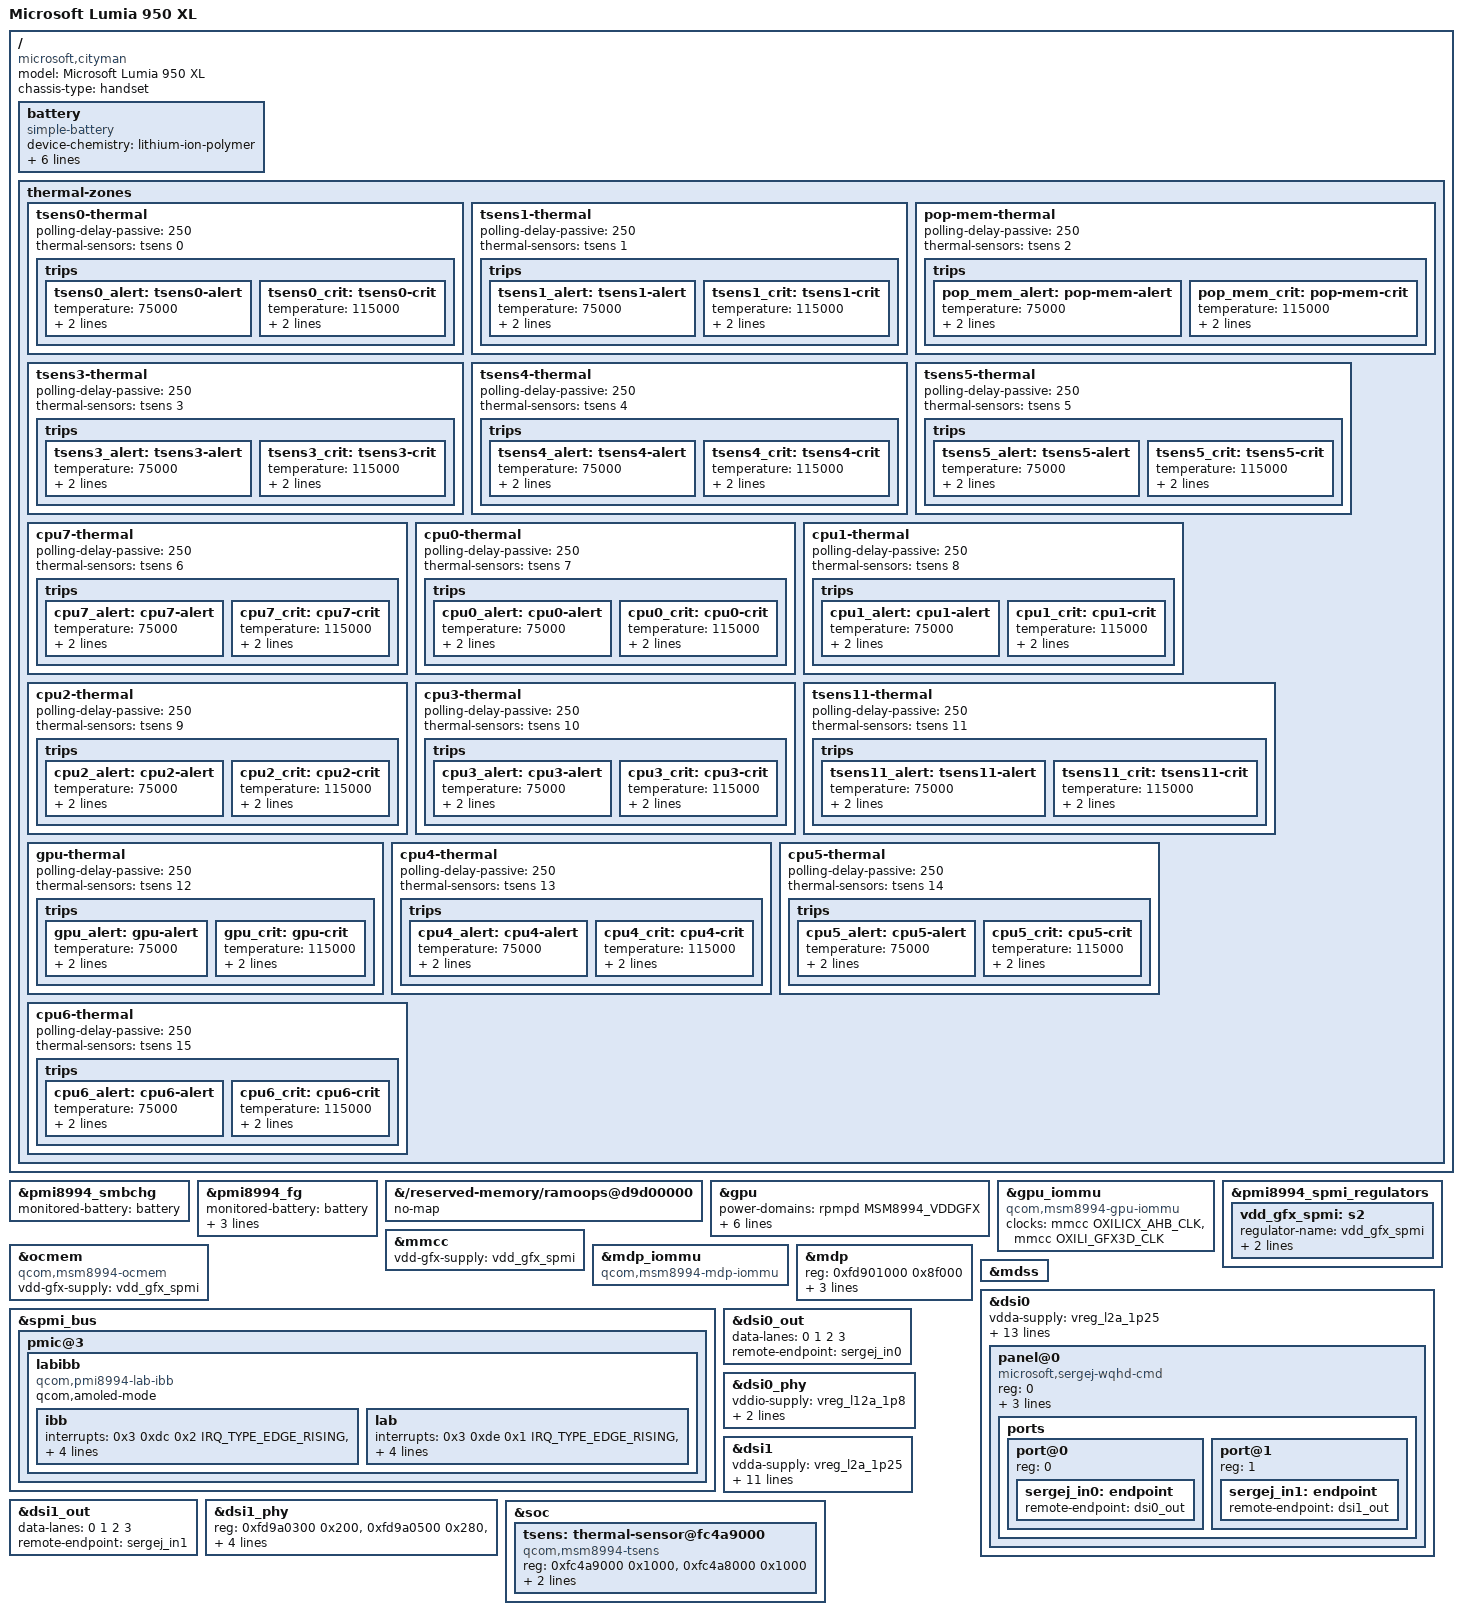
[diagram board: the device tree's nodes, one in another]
// SPDX-License-Identifier: BSD-3-Clause
/*
 * Copyright (c) 2020, Konrad Dybcio <konrad.dybcio@somainline.org>
 * Copyright (c) 2020, Gustave Monce <gustave.monce@outlook.com>
 */

/dts-v1/;

#include "msm8994.dtsi"
#include "msm8994-msft-lumia-octagon.dtsi"
#include <dt-bindings/interrupt-controller/arm-gic.h>
#include <dt-bindings/interrupt-controller/irq.h>
#include <dt-bindings/gpio/gpio.h>

/ {
	model = "Microsoft Lumia 950 XL";
	compatible = "microsoft,cityman", "qcom,msm8994";
	chassis-type = "handset";

	/* BV-T4D 3340 mAh. ID 330 kΩ is on &pmi8994_fg. */
	battery: battery {
		compatible = "simple-battery";
		device-chemistry = "lithium-ion-polymer";
		charge-full-design-microamp-hours = <3340000>;
		voltage-max-design-microvolt = <4400000>;
		voltage-min-design-microvolt = <2800000>;
		charge-term-current-microamp = <100000>;
		constant-charge-current-max-microamp = <2000000>;
		constant-charge-voltage-max-microvolt = <4350000>;
	};
};

&pmi8994_smbchg {
	monitored-battery = <&battery>;
};

&pmi8994_fg {
	monitored-battery = <&battery>;
	qcom,battery-type = "microsoft_bvt4d_3340mah";
	qcom,fg-profile-data = [
		F2 83 90 7D AC 81 23 7C
		64 83 55 74 27 89 0D 94
		38 82 29 98 0A B5 17 C0
		58 18 FF 83 9D 7D A8 81
		1A 7C 5D 83 FF 4E 84 82
		25 8E 17 82 B4 9A F7 BD
		59 CB 58 0E 71 0D 1F 5A
		14 70 B8 FE E4 45 49 37
		77 41 00 00 23 47 7A 32
		AF 31 00 00 00 00 00 00
		00 00 00 00 80 6B 23 6A
		EA 68 75 81 61 74 D9 62
		BE 6B 31 80 25 6E E6 59
		80 80 A6 C0 0F F0 60 3A
		5E A0 71 0C 28 00 FF 36
		F0 11 30 03 00 00 00 0C
	];
};

/*
 * Octagon ramoops@d9d00000 has //no-map commented. Proven on this
 * WP BootMgr path (Talkman ramtop): the window only survives
 * sysrq-b with no-map. Same octagon 3 GiB map on Cityman.
 */
&{/reserved-memory/ramoops@d9d00000} {
	no-map;
};

/*
 * Catalog 0x04030000. gfx-mem ICC is BIMC GFX3D. Vote RPM VDDGFX
 * (gfx_s2b) on the GPU. Do not put OXILI_GX_GDSC on &gpu or
 * gpu_iommu — that collapses the wrong domain at bind.
 */
&gpu {
	status = "okay";
	power-domains = <&rpmpd MSM8994_VDDGFX>;
	required-opps = <&rpmpd_opp_svs_soc>;
	/* BIMC GFX3D master, not MDP port0 (that is mdss). */
	interconnects = <&bimc BIMC_MAS_GRAPHICS_3D &bimc BIMC_SLV_EBI_CH0>,
			<&ovirt OCMEM_MAS_GFX3D &ovirt OCMEM_SLV_OCMEM_GFX>;
	interconnect-names = "gfx-mem", "ocmem";
	/*
	 * 3.10 gfx3d_user carries SIDs 0 and 1. Stock dtsi only
	 * lists 0, so SID 1 would miss the user context bank.
	 */
	iommus = <&gpu_iommu 0>, <&gpu_iommu 1>;
};

/*
 * 8994 GPU SMMU has no AXI bus clock (downstream kgsl_iommu uses
 * core_clk=gfx3d + iface_clk=oxilicx_ahb). tbu must stay gfx3d.
 * Own compatible so the 8994 BFB table is not applied to 8974.
 */
&gpu_iommu {
	compatible = "qcom,msm8994-gpu-iommu";
	clocks = <&mmcc OXILICX_AHB_CLK>,
		 <&mmcc OXILI_GFX3D_CLK>;
	clock-names = "iface", "tbu";
};

/*
 * VDD_GFX via PMI8994 SPMI s2. The RPM SMD vdd_gfx node hangs
 * this board. 8996 boards wire mmcc the same way. Consumer vote,
 * not always-on.
 */
&pmi8994_spmi_regulators {
	vdd_gfx_spmi: s2 {
		regulator-name = "vdd_gfx_spmi";
		regulator-min-microvolt = <1015000>;
		regulator-max-microvolt = <1015000>;
	};
};

&mmcc {
	vdd-gfx-supply = <&vdd_gfx_spmi>;
};

/*
 * 8994 OCMEM is four regions / 2 MiB (not 8974's three / 1.5 MiB).
 * vdd-gfx keeps the controller powered; unused-disable of this rail
 * makes later TZ ocmem_lock hang. Consumer vote, not always-on.
 */
&ocmem {
	compatible = "qcom,msm8994-ocmem";
	vdd-gfx-supply = <&vdd_gfx_spmi>;
};

/*
 * 3.10 msm8994-iommu.dtsi MDP BFB (0x2000 impl-def bias removed).
 * Stock msm8994.dtsi is qcom,msm8974-mdp-iommu (8974 BFB). Keep
 * 8994 addresses 0xfd9cc000 / 0xfd9d4000. Do not paste Talkman
 * 0xfd9b4000.
 */
&mdp_iommu {
	compatible = "qcom,msm8994-mdp-iommu";
};

/*
 * CAF msm8994-mdss.dtsi (mmo + OnePlus 8994): mdp_phys 0xfd900000,
 * qcom,mdss-mdp-reg-offset = <0x1000> → HW_VERSION at 0xfd901000.
 * msm8994.dtsi maps MDP at 0xfd900100 / 0x98000, which overlaps CAF
 * DSI0 0xfd998000. Talkman #46: 0xfd900100 reads 0; 0xfd901000 is
 * 0x100a0000. Same offset on 8994 CAF. Size 0x8f000 = 0x90000-0x1000,
 * ending 0xfd990000, before DSI0. Do not paste Talkman DSI1
 * (8992 map) or Talkman MDP SMMU (8994 VBIF/SMMU stay
 * 0xfd9c8000 / 0xfd9cc000).
 */
&mdp {
	reg = <0xfd901000 0x8f000>;
	/*
	 * 3.10 qcom,mdss-en-svs-high + footswitch vdd-cx at
	 * SVS_SOC. Parent MDSS_GDSC does not vote CX; after
	 * POWER_OFF the SoC rail can sit at SVS_KRAIT while
	 * AHB still programs SSPP and AXI never fetches
	 * (CURRENT=0, DSI CMD_MDP_BUSY). 8998 mdp votes
	 * rpmpd the same way. NOM is above SVS+ for 400 MHz
	 * dual-LM. Released when MDP runtime-suspends.
	 */
	power-domains = <&rpmpd MSM8994_VDDCX>, <&rpmpd MSM8994_VDDMX>;
	power-domain-names = "cx", "mx";
	required-opps = <&rpmpd_opp_nom>, <&rpmpd_opp_nom>;
};

/*
 * PMI8994 LAB @ 0xde00 / IBB @ 0xdc00 (SID 3). 3.10 msm8994-chi.dtsi
 * enables &labibb with qpnp,qpnp-labibb-mode = "oled" (AMOLED; CAF
 * string is "amoled"). LCD_AMOLED_SEL 0x44 BIT(7), LAB 4.6 V / IBB
 * 4.0 V init-amoled, IBB discharge 32 kOhm. LCD mode on this OLED
 * is a green tint and blacks that still emit (Snaccy 2026-08-27).
 * Mainline msm8994_dsi_cfg bulk_gets lab_reg / ibb_reg. Probe reads
 * PERPH_TYPE (0x24 / 0x20); do not stub.
 */
&spmi_bus {
	pmic@3 {
		labibb {
			compatible = "qcom,pmi8994-lab-ibb", "qcom,pmi8998-lab-ibb";
			qcom,amoled-mode;

			ibb: ibb {
				interrupts = <0x3 0xdc 0x2 IRQ_TYPE_EDGE_RISING>,
					     <0x3 0xdc 0x0 IRQ_TYPE_LEVEL_LOW>;
				interrupt-names = "sc-err", "ocp";
				regulator-min-microvolt = <4000000>;
				regulator-max-microvolt = <6000000>;
				qcom,discharge-resistor-kohms = <32>;
			};

			lab: lab {
				interrupts = <0x3 0xde 0x1 IRQ_TYPE_EDGE_RISING>,
					     <0x3 0xde 0x0 IRQ_TYPE_LEVEL_LOW>;
				interrupt-names = "sc-err", "ocp";
				regulator-min-microvolt = <4600000>;
				regulator-max-microvolt = <6000000>;
				qcom,soft-start-us = <800>;
			};
		};
	};
};

&mdss {
	status = "okay";
};

/*
 * CAF 8994 DSI0 0xfd998000 / DSI1 0xfd9a0000. Keep qcom,dsi-phy-20nm
 * (dsi_phy_20nm_cfgs io_start 0xfd998500 / 0xfd9a0500 + pll_init).
 * Do not stamp the 8992 20nm PHY compatible (that table's
 * io_start is the 8992 PHY map, not these 8994 addresses).
 *
 * Supplies: CAF msm8994-mdss + Snaccy cityman RPM L14/L12/L28/L2.
 * 3.10 mmo-common mdss.dtsi points host vddio at pm8994_s4; do not
 * copy Talkman SPMI s4 without a Cityman RPM timeout fact.
 * msm8994_dsi_cfg still bulk_gets vdda/vddio/vcca/vdd/lab_reg/ibb_reg.
 *
 * Dual-DSI: 3.10 sergej DSI0 cmd-sync-wait-broadcast; DSI1 broadcast +
 * cmd-sync-wait-trigger. Mainline: dual-dsi-mode + sync-dual-dsi on
 * both, master-dsi on DSI0.
 *
 * CAF clock_mmss parents byte1/pclk1 from PLL0. 20nm pll_init skips
 * the byte tree on phy->id != DSI_0. Override BYTE1/PCLK1 parents here,
 * not in msm8994.dtsi.
 *
 * Reset gpio78 (octagon DISPLAY_RESET_N, 3.10 platform-reset-gpio).
 * Panel timings from 3.10 dsi-panel-sergej-wqhd-dualdsi-cmd.dtsi.
 */
&dsi0 {
	status = "okay";
	#address-cells = <1>;
	#size-cells = <0>;

	vdda-supply = <&vreg_l2a_1p25>;
	vddio-supply = <&vreg_l12a_1p8>;
	vcca-supply = <&vreg_l28a_1p0>;
	vdd-supply = <&vreg_l14a_1p8>;
	lab_reg-supply = <&lab>;
	ibb_reg-supply = <&ibb>;

	pinctrl-names = "default", "sleep";
	pinctrl-0 = <&mdss_dsi_default &mdss_te_default>;
	pinctrl-1 = <&mdss_dsi_sleep &mdss_te_sleep>;

	qcom,dual-dsi-mode;
	qcom,sync-dual-dsi;
	qcom,master-dsi;

	/*
	 * 3.10 msm8994-mdss.dtsi: mmss_misc_phys 0xfd828000,
	 * ulp-clamp 0x14, phyreset 0x108. CAF listed size 0x108;
	 * map 0x110 so the phyreset write is inside the window.
	 */
	reg = <0xfd998000 0x260>, <0xfd828000 0x110>;
	reg-names = "dsi_ctrl", "mmss_misc";
	qcom,mmss-ulp-clamp-ctrl-offset = <0x14>;
	qcom,mmss-phyreset-ctrl-offset = <0x108>;

	panel@0 {
		compatible = "microsoft,sergej-wqhd-cmd";
		reg = <0>;

		reset-gpios = <&tlmm 78 GPIO_ACTIVE_LOW>;

		/* 3.10 dsi-panel-sergej-wqhd-dualdsi-cmd.dtsi */
		qcom,mdss-dsi-panel-timings = [97 5A 3E 00 9A 9A 48 5E 4B 03 04 00];

		ports {
			#address-cells = <1>;
			#size-cells = <0>;

			port@0 {
				reg = <0>;
				sergej_in0: endpoint {
					remote-endpoint = <&dsi0_out>;
				};
			};

			port@1 {
				reg = <1>;
				sergej_in1: endpoint {
					remote-endpoint = <&dsi1_out>;
				};
			};
		};
	};
};

&dsi0_out {
	data-lanes = <0 1 2 3>;
	remote-endpoint = <&sergej_in0>;
};

&dsi0_phy {
	status = "okay";

	vddio-supply = <&vreg_l12a_1p8>;
	vcca-supply = <&vreg_l28a_1p0>;
	/* 3.10 mmo-common &mdss_dsi0 qcom,regulator-ldo-mode */
	qcom,dsi-phy-regulator-ldo-mode;
};

&dsi1 {
	status = "okay";

	vdda-supply = <&vreg_l2a_1p25>;
	vddio-supply = <&vreg_l12a_1p8>;
	vcca-supply = <&vreg_l28a_1p0>;
	vdd-supply = <&vreg_l14a_1p8>;
	lab_reg-supply = <&lab>;
	ibb_reg-supply = <&ibb>;

	qcom,dual-dsi-mode;
	qcom,sync-dual-dsi;

	reg = <0xfd9a0000 0x260>, <0xfd828000 0x110>;
	reg-names = "dsi_ctrl", "mmss_misc";
	qcom,mmss-ulp-clamp-ctrl-offset = <0x14>;
	qcom,mmss-phyreset-ctrl-offset = <0x108>;

	/*
	 * CAF 8994 clock_mmss and 3.10 mdss_dsi@fd9a0000 parent
	 * byte1_src/pclk1_src to mdss_dsi0_pll muxes. msm8994.dtsi
	 * parents BYTE1_CLK_SRC/PCLK1_CLK_SRC to dsi1_phy 0/1. PLL1
	 * skips the byte tree. Parent both to dsi0_phy (CAF PLL0).
	 */
	assigned-clock-parents = <&dsi0_phy 0>, <&dsi0_phy 1>;
};

&dsi1_out {
	data-lanes = <0 1 2 3>;
	remote-endpoint = <&sergej_in1>;
};

&dsi1_phy {
	status = "okay";

	/*
	 * CAF msm8994-mdss.dtsi maps DSI1 phy_regulator at the DSI0
	 * window 0xfd998780 (shared), not mainline 0xfd9a0780.
	 */
	reg = <0xfd9a0300 0x200>,
	      <0xfd9a0500 0x280>,
	      <0xfd998780 0x30>;
	reg-names = "dsi_pll", "dsi_phy", "dsi_phy_regulator";

	vddio-supply = <&vreg_l12a_1p8>;
	vcca-supply = <&vreg_l28a_1p0>;
	qcom,dsi-phy-regulator-ldo-mode;
};

/*
 * 8994 TSENS is v1, 16 sensors, GIC SPI 184. Stays in cityman.dts
 * because msm8992.dtsi includes msm8994.dtsi and 8992 uses a
 * different 13-sensor fuse map.
 */
&soc {
	tsens: thermal-sensor@fc4a9000 {
		compatible = "qcom,msm8994-tsens", "qcom,tsens-v1";
		reg = <0xfc4a9000 0x1000>,
		      <0xfc4a8000 0x1000>;
		#qcom,sensors = <16>;
		interrupts = <GIC_SPI 184 IRQ_TYPE_LEVEL_HIGH>;
		interrupt-names = "uplow";
		#thermal-sensor-cells = <1>;
	};
};

/* 3.10 qcom,sensor-information aliases. No cooling-maps. */
/ {
	thermal-zones {
		tsens0-thermal {
			polling-delay-passive = <250>;
			thermal-sensors = <&tsens 0>;
			trips {
				tsens0_alert: tsens0-alert {
					temperature = <75000>;
					hysteresis = <2000>;
					type = "passive";
				};
				tsens0_crit: tsens0-crit {
					temperature = <115000>;
					hysteresis = <2000>;
					type = "critical";
				};
			};
		};

		tsens1-thermal {
			polling-delay-passive = <250>;
			thermal-sensors = <&tsens 1>;
			trips {
				tsens1_alert: tsens1-alert {
					temperature = <75000>;
					hysteresis = <2000>;
					type = "passive";
				};
				tsens1_crit: tsens1-crit {
					temperature = <115000>;
					hysteresis = <2000>;
					type = "critical";
				};
			};
		};

		pop-mem-thermal {
			polling-delay-passive = <250>;
			thermal-sensors = <&tsens 2>;
			trips {
				pop_mem_alert: pop-mem-alert {
					temperature = <75000>;
					hysteresis = <2000>;
					type = "passive";
				};
				pop_mem_crit: pop-mem-crit {
					temperature = <115000>;
					hysteresis = <2000>;
					type = "critical";
				};
			};
		};

		tsens3-thermal {
			polling-delay-passive = <250>;
			thermal-sensors = <&tsens 3>;
			trips {
				tsens3_alert: tsens3-alert {
					temperature = <75000>;
					hysteresis = <2000>;
					type = "passive";
				};
				tsens3_crit: tsens3-crit {
					temperature = <115000>;
					hysteresis = <2000>;
					type = "critical";
				};
			};
		};

		tsens4-thermal {
			polling-delay-passive = <250>;
			thermal-sensors = <&tsens 4>;
			trips {
				tsens4_alert: tsens4-alert {
					temperature = <75000>;
					hysteresis = <2000>;
					type = "passive";
				};
				tsens4_crit: tsens4-crit {
					temperature = <115000>;
					hysteresis = <2000>;
					type = "critical";
				};
			};
		};

		tsens5-thermal {
			polling-delay-passive = <250>;
			thermal-sensors = <&tsens 5>;
			trips {
				tsens5_alert: tsens5-alert {
					temperature = <75000>;
					hysteresis = <2000>;
					type = "passive";
				};
				tsens5_crit: tsens5-crit {
					temperature = <115000>;
					hysteresis = <2000>;
					type = "critical";
				};
			};
		};

		cpu7-thermal {
			polling-delay-passive = <250>;
			thermal-sensors = <&tsens 6>;
			trips {
				cpu7_alert: cpu7-alert {
					temperature = <75000>;
					hysteresis = <2000>;
					type = "passive";
				};
				cpu7_crit: cpu7-crit {
					temperature = <115000>;
					hysteresis = <2000>;
					type = "critical";
				};
			};
		};

		cpu0-thermal {
			polling-delay-passive = <250>;
			thermal-sensors = <&tsens 7>;
			trips {
				cpu0_alert: cpu0-alert {
					temperature = <75000>;
					hysteresis = <2000>;
					type = "passive";
				};
				cpu0_crit: cpu0-crit {
					temperature = <115000>;
					hysteresis = <2000>;
					type = "critical";
				};
			};
		};

		cpu1-thermal {
			polling-delay-passive = <250>;
			thermal-sensors = <&tsens 8>;
			trips {
				cpu1_alert: cpu1-alert {
					temperature = <75000>;
					hysteresis = <2000>;
					type = "passive";
				};
				cpu1_crit: cpu1-crit {
					temperature = <115000>;
					hysteresis = <2000>;
					type = "critical";
				};
			};
		};

		cpu2-thermal {
			polling-delay-passive = <250>;
			thermal-sensors = <&tsens 9>;
			trips {
				cpu2_alert: cpu2-alert {
					temperature = <75000>;
					hysteresis = <2000>;
					type = "passive";
				};
				cpu2_crit: cpu2-crit {
					temperature = <115000>;
					hysteresis = <2000>;
					type = "critical";
				};
			};
		};

		cpu3-thermal {
			polling-delay-passive = <250>;
			thermal-sensors = <&tsens 10>;
			trips {
				cpu3_alert: cpu3-alert {
					temperature = <75000>;
					hysteresis = <2000>;
					type = "passive";
				};
				cpu3_crit: cpu3-crit {
					temperature = <115000>;
					hysteresis = <2000>;
					type = "critical";
				};
			};
		};

		tsens11-thermal {
			polling-delay-passive = <250>;
			thermal-sensors = <&tsens 11>;
			trips {
				tsens11_alert: tsens11-alert {
					temperature = <75000>;
					hysteresis = <2000>;
					type = "passive";
				};
				tsens11_crit: tsens11-crit {
					temperature = <115000>;
					hysteresis = <2000>;
					type = "critical";
				};
			};
		};

		gpu-thermal {
			polling-delay-passive = <250>;
			thermal-sensors = <&tsens 12>;
			trips {
				gpu_alert: gpu-alert {
					temperature = <75000>;
					hysteresis = <2000>;
					type = "passive";
				};
				gpu_crit: gpu-crit {
					temperature = <115000>;
					hysteresis = <2000>;
					type = "critical";
				};
			};
		};

		cpu4-thermal {
			polling-delay-passive = <250>;
			thermal-sensors = <&tsens 13>;
			trips {
				cpu4_alert: cpu4-alert {
					temperature = <75000>;
					hysteresis = <2000>;
					type = "passive";
				};
				cpu4_crit: cpu4-crit {
					temperature = <115000>;
					hysteresis = <2000>;
					type = "critical";
				};
			};
		};

		cpu5-thermal {
			polling-delay-passive = <250>;
			thermal-sensors = <&tsens 14>;
			trips {
				cpu5_alert: cpu5-alert {
					temperature = <75000>;
					hysteresis = <2000>;
					type = "passive";
				};
				cpu5_crit: cpu5-crit {
					temperature = <115000>;
					hysteresis = <2000>;
					type = "critical";
				};
			};
		};

		cpu6-thermal {
			polling-delay-passive = <250>;
			thermal-sensors = <&tsens 15>;
			trips {
				cpu6_alert: cpu6-alert {
					temperature = <75000>;
					hysteresis = <2000>;
					type = "passive";
				};
				cpu6_crit: cpu6-crit {
					temperature = <115000>;
					hysteresis = <2000>;
					type = "critical";
				};
			};
		};
	};
};
